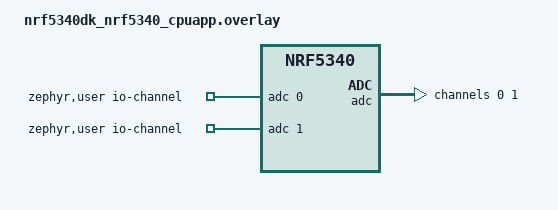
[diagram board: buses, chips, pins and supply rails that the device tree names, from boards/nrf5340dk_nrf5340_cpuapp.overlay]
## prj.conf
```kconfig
# ── ADC ───────────────────────────────────────────────────────────────────────
CONFIG_ADC=y
CONFIG_ADC_ASYNC=y
CONFIG_GPIO=y
# Power Managment
CONFIG_PM=y
CONFIG_PM_DEVICE=y
CONFIG_PM_DEVICE_RUNTIME=y

# ── Logging (RTT, same as peripheral_uart reference) ──────────────────────────
CONFIG_LOG=y
CONFIG_USE_SEGGER_RTT=y
CONFIG_LOG_BACKEND_RTT=y
CONFIG_LOG_BACKEND_UART=n
CONFIG_LOG_PRINTK=n
CONFIG_CONSOLE=y
CONFIG_UART_CONSOLE=y

# ── BLE ───────────────────────────────────────────────────────────────────────
CONFIG_BT=y
CONFIG_BT_PERIPHERAL=y
CONFIG_BT_DEVICE_NAME="Device_ADC"
CONFIG_BT_MAX_CONN=1

# ── NUS service ───────────────────────────────────────────────────────────────
CONFIG_BT_NUS=y

# nRF5340: use host PRNG, not HCI for entropy (required on this SoC)
CONFIG_BT_HOST_CRYPTO_PRNG=y
CONFIG_ENTROPY_BT_HCI=n

# Increase ATT MTU so batch packets (37 bytes payload) fit in one notify.
# ATT header = 3 bytes → need MTU >= 40; set 65 for headroom.
CONFIG_BT_L2CAP_TX_MTU=65
CONFIG_BT_BUF_ACL_TX_SIZE=69
CONFIG_BT_BUF_ACL_RX_SIZE=69

# ── DK LEDs (connection status on LED2) ───────────────────────────────────────
CONFIG_DK_LIBRARY=y

# ── System ────────────────────────────────────────────────────────────────────
CONFIG_HEAP_MEM_POOL_SIZE=2048
CONFIG_SYSTEM_WORKQUEUE_STACK_SIZE=2048
CONFIG_ASSERT=y
```

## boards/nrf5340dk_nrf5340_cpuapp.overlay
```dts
/*
 * SPDX-License-Identifier: Apache-2.0
 *
 * Copyright (c) 2022 Nordic Semiconductor ASA
 */

/ {
	zephyr,user {
		io-channels = <&adc 0>, <&adc 1>;
	};
};

&adc {
	#address-cells = <1>;
	#size-cells = <0>;
	status = "okay";
	channel@0 {
		reg = <0>;
		zephyr,gain = "ADC_GAIN_1_6";
		zephyr,reference = "ADC_REF_INTERNAL";
		zephyr,acquisition-time = <ADC_ACQ_TIME_DEFAULT>;
		zephyr,input-positive = <NRF_SAADC_AIN0>; /* P0.02 for nRF52xx, P0.04 for nRF5340 */
		zephyr,resolution = <12>;
	};
	channel@1 {
		reg = <1>;
		zephyr,gain = "ADC_GAIN_1_6";
		zephyr,reference = "ADC_REF_INTERNAL";
		zephyr,acquisition-time = <ADC_ACQ_TIME_DEFAULT>;
		zephyr,input-positive = <NRF_SAADC_AIN1>;
		zephyr,resolution = <12>;
	};
};
```

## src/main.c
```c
/* SPDX-License-Identifier: Apache-2.0
 *
 * Wiring layer only.  Does not reference any ADC or BLE implementation
 * details directly — those are encapsulated in their respective modules.
 */

#include <zephyr/kernel.h>
#include <zephyr/logging/log.h>

#include "adc_sampler.h"
// #include "ble_sender.h"

LOG_MODULE_REGISTER(main, LOG_LEVEL_INF);

int main(void)
{
	int err;

	err = adc_sampler_init();
	if (err) {
		LOG_ERR("adc_sampler_init: %d", err);
		return err;
	}

	err = ble_sender_init();
	if (err) {
		LOG_ERR("ble_sender_init: %d", err);
		return err;
	}

	adc_sampler_start();

	return 0;
}
```

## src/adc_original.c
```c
// /*
//  * Copyright (c) 2024 Nordic Semiconductor ASA
//  *
//  * SPDX-License-Identifier: LicenseRef-Nordic-5-Clause
//  */

// #include <inttypes.h>
// #include <stddef.h>
// #include <stdint.h>

// #include <zephyr/kernel.h>
// #include <zephyr/device.h>
// #include <zephyr/devicetree.h>
// #include <zephyr/logging/log.h>
// #include <zephyr/drivers/adc.h>
// #include <zephyr/sys/util.h>

/* #define DT_SPEC_AND_COMMA(node_id, prop, idx) \
 	ADC_DT_SPEC_GET_BY_IDX(node_id, idx),
*/

// /* STEP 3.2 - Define a variable of type adc_dt_spec for each channel */
// // static const struct adc_dt_spec adc_channel = ADC_DT_SPEC_GET(DT_PATH(zephyr_user)); // single channel

// static const struct adc_dt_spec adc_channels[] = {
//       DT_FOREACH_PROP_ELEM(DT_PATH(zephyr_user), io_channels, DT_SPEC_AND_COMMA)
// };

// LOG_MODULE_REGISTER(MultiChannel_ADC, LOG_LEVEL_DBG);

// int main(void) {
// 	int err;
// 	uint32_t count = 0;

// 	/* STEP 4.1 - Define a variable of type adc_sequence and a buffer of type uint16_t */
//       int16_t buf;
//       struct adc_sequence sequence = {
//             .buffer = &buf,
//             .buffer_size = sizeof(buf),
//       };

//       // Configure channels individually
//       for (size_t i = 0U; i < ARRAY_SIZE(adc_channels); i++) {
//             /* STEP 3.3 - validate that the ADC peripheral (SAADC) is ready */
//             if (!adc_is_ready_dt(&adc_channels[i])) {
//                   LOG_ERR("ADC controller devivce %s not ready", adc_channels[i].dev->name);
//                   return 0;
//             }
//             /* STEP 3.4 - Setup the ADC channel */
//             err = adc_channel_setup_dt(&adc_channels[i]);
//             if (err < 0) {
//                   LOG_ERR("Could not setup channel #%d (%d)", 0, err);
//                   return 0;
//             }
//       }

// 	while (1) {
//             for (size_t i = 0U; i < ARRAY_SIZE(adc_channels); i++) { 
//                   /* STEP 4.2 - Initialize the ADC sequence */
//                   err = adc_sequence_init_dt(&adc_channels[i], &sequence);
//                   if (err < 0) {
//                         LOG_ERR("Could not initialize sequence");
//                         return 0;
//                   }

//                   int32_t val_mv;

//                   /* STEP 5 - Read a sample from the ADC */
//                   err = adc_read(adc_channels[i].dev, &sequence);
//                   if (err < 0) {
//                         LOG_ERR("Could not read (%d)", err);
//                         continue;
//                   }

//                   val_mv = (int)buf;
//                   LOG_INF("ADC reading[%u]: %s, channel %d: Raw: %d", count++, adc_channels[i].dev->name,
//                         adc_channels[i].channel_id, val_mv);

//                   /* STEP 6 - Convert raw value to mV*/
//                   err = adc_raw_to_millivolts_dt(&adc_channels[i], &val_mv);
//                   if (err < 0) {
//                         LOG_WRN(" (value in mV not available)\n");
//                   } else {
//                         LOG_INF(" = %d mV", val_mv);
//                   }

//                   k_sleep(K_MSEC(1000));
//             }
// 	}
// 	return 0;
// }
```

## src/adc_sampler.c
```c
/* SPDX-License-Identifier: Apache-2.0 */
#include "adc_sampler.h"

#include <zephyr/kernel.h>
#include <zephyr/device.h>
#include <zephyr/devicetree.h>
#include <zephyr/drivers/adc.h>
#include <zephyr/logging/log.h>
#include <zephyr/sys/util.h>

LOG_MODULE_REGISTER(adc_sampler, LOG_LEVEL_DBG);

#define DT_SPEC_AND_COMMA(node_id, prop, idx) \
	ADC_DT_SPEC_GET_BY_IDX(node_id, idx),

static const struct adc_dt_spec adc_channels[] = {
	DT_FOREACH_PROP_ELEM(DT_PATH(zephyr_user), io_channels, DT_SPEC_AND_COMMA)
};

BUILD_ASSERT(ARRAY_SIZE(adc_channels) == ADC_NUM_CHANNELS,
	     "overlay io-channels count must equal ADC_NUM_CHANNELS");

/* ── Queue (contract with BLE consumer) ──────────────────────────────────── */

// For BLE:
K_MSGQ_DEFINE(adc_sample_q, sizeof(struct adc_sample), 20, 4);

/* ── Internal state ───────────────────────────────────────────────────────── */

#define SAMPLE_INTERVAL_MS 10   /* 100 Hz */

static struct k_timer sample_timer;
static K_SEM_DEFINE(sample_sem, 0, 1);
static volatile bool running;

static void timer_fn(struct k_timer *t)
{
	ARG_UNUSED(t);
	k_sem_give(&sample_sem);
}

/* ── Async Read (phase 2) ───────
 *
 * Thread yields during conversion and the CPU can enter sleep between samples.
 *
 * TODO (DMA — phase 3, full CPU sleep): Configure SAADC scan mode triggered
 * by TIMER via DPPI; handle the SAADC END event in a callback that writes
 * directly into adc_sample_q. The CPU can then stay in System ON Low Power
 * between callbacks entirely.
*/

static void sample_all_channels_async(struct adc_sample *out)
{
	int16_t buf;
	struct adc_sequence sequence = {
		.buffer      = &buf,
		.buffer_size = sizeof(buf),
	};

	static struct k_poll_signal async_sig = K_POLL_SIGNAL_INITIALIZER(async_sig);
	struct k_poll_event async_evt = 
		K_POLL_EVENT_INITIALIZER(K_POLL_TYPE_SIGNAL, 
						K_POLL_MODE_NOTIFY_ONLY, 
						&async_sig);

	out->timestamp_us = k_cyc_to_us_floor32(k_cycle_get_32());

	for (size_t i = 0; i < ARRAY_SIZE(adc_channels); i++) {
		// Initialize sequence
		int err = adc_sequence_init_dt(&adc_channels[i], &sequence);
		if (err < 0) {
			LOG_ERR("sequence init ch%u: %d", i, err);
			out->raw[i] = 0;
			out->mv[i]  = 0;
			continue;
		}

		// Reset signal before each read
		k_poll_signal_reset(&async_sig);
		async_evt.state = K_POLL_STATE_NOT_READY;

		err = adc_read_async(adc_channels[i].dev, &sequence, &async_sig);
		if (err < 0) {
			LOG_ERR("adc_read ch%u: %d", i, err);
			out->raw[i] = 0;
			out->mv[i]  = 0;
			continue;
		}

		// Sleep while waiting for completion
		err = k_poll(&async_evt, 1, K_FOREVER);
		if (err < 0) {
			LOG_ERR("k_poll ch%u: %d", i, err);
			out->raw[i] = 0;
			out->mv[i]  = 0;
			continue;
		}

		int32_t val_mv = (int32_t)buf;
		out->raw[i] = buf;

		LOG_INF("ADC reading[%u us]: %s, channel %d: Raw: %d",
			out->timestamp_us,
			adc_channels[i].dev->name,
			adc_channels[i].channel_id,
			out->raw[i]);

		err = adc_raw_to_millivolts_dt(&adc_channels[i], &val_mv);
		if (err < 0) {
			LOG_WRN("ch%u: mV not available", i);
			out->mv[i] = 0;
		} else {
			LOG_INF("ch%u: %d mV", i, val_mv);
			out->mv[i] = val_mv;
		}
	}
}

/* ── Sampler thread ───────────────────────────────────────────────────────── */

static void sampler_thread_fn(void *a, void *b, void *c)
{
	ARG_UNUSED(a);
	ARG_UNUSED(b);
	ARG_UNUSED(c);

	while (1) {
		k_sem_take(&sample_sem, K_FOREVER);

		if (!running) {
			continue;
		}

		struct adc_sample s;
		// sample_all_channels(&s);
		sample_all_channels_async(&s);

		// For BLE:
		if (k_msgq_put(&adc_sample_q, &s, K_NO_WAIT) != 0) {
			LOG_WRN("queue full, sample dropped");
		}
	}
}

K_THREAD_DEFINE(sampler_tid, 1024, sampler_thread_fn,
		NULL, NULL, NULL, 5, 0, 0);

/* ── Public API ───────────────────────────────────────────────────────────── */

int adc_sampler_init(void)
{
	for (size_t i = 0; i < ARRAY_SIZE(adc_channels); i++) {
		if (!adc_is_ready_dt(&adc_channels[i])) {
			LOG_ERR("ADC device %s not ready",
				adc_channels[i].dev->name);
			return -ENODEV;
		}

		int err = adc_channel_setup_dt(&adc_channels[i]);
		if (err < 0) {
			LOG_ERR("channel setup ch%u: %d", i, err);
			return err;
		}
	}

	k_timer_init(&sample_timer, timer_fn, NULL);
	LOG_INF("ADC sampler ready, %u channels", ADC_NUM_CHANNELS);
	return 0;
}

void adc_sampler_start(void)
{
	running = true;
	k_timer_start(&sample_timer, K_NO_WAIT, K_MSEC(SAMPLE_INTERVAL_MS));
	LOG_INF("ADC sampling started @ %d Hz", 1000 / SAMPLE_INTERVAL_MS);
}

void adc_sampler_stop(void)
{
	running = false;
	k_timer_stop(&sample_timer);
	LOG_INF("ADC sampling stopped");
}
```

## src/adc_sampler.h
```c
/* SPDX-License-Identifier: Apache-2.0 */
#ifndef ADC_SAMPLER_H_
#define ADC_SAMPLER_H_

#include <zephyr/kernel.h>
#include <stdint.h>

/* Must match the number of channels declared in boards/*.overlay */
#define ADC_NUM_CHANNELS 2

/* ── Contract ─────────────────────────────────────────────────────────────── */

struct adc_sample {
	uint32_t timestamp_us;
	int16_t  raw[ADC_NUM_CHANNELS];
	int32_t  mv[ADC_NUM_CHANNELS];
};

/* Shared queue: ADC is the producer, BLE sender is the consumer.
 * Depth 20 = 200 ms of headroom at 100 Hz.
 * Defined in adc_sampler.c; BLE side includes this header for the extern. */
extern struct k_msgq adc_sample_q;

/* ── API ──────────────────────────────────────────────────────────────────── */

int  adc_sampler_init(void);
void adc_sampler_start(void);
void adc_sampler_stop(void);

#endif /* ADC_SAMPLER_H_ */
```
